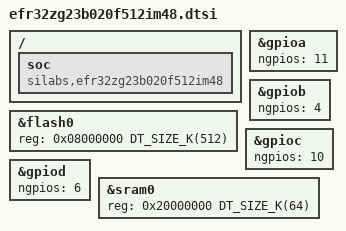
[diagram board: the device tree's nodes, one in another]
/*
 * Copyright (c) 2024 Yishai Jaffe
 * Copyright (c) 2026 Silicon Laboratories Inc.
 *
 * SPDX-License-Identifier: Apache-2.0
 */

#include <mem.h>
#include <silabs/xg23/efr32zg23.dtsi>

/ {
	soc {
		compatible = "silabs,efr32zg23b020f512im48", "silabs,efr32zg23", "silabs,xg23",
			     "silabs,efr32", "simple-bus";
	};
};

&flash0 {
	reg = <0x08000000 DT_SIZE_K(512)>;
};

&gpioa {
	ngpios = <11>;
};

&gpiob {
	ngpios = <4>;
};

&gpioc {
	ngpios = <10>;
};

&gpiod {
	ngpios = <6>;
};

&sram0 {
	reg = <0x20000000 DT_SIZE_K(64)>;
};
